VERSION "HIPBNYYYYYYYYYYYYYYYYYYYYYYYYYYYYYYYYYYYYY/4/%%%/4/'%**4YYY///"

NS_ :

BS_:

BU_: WaveSculptor20

BO_ 1024 IDInfo: 8 WaveSculptor20
 SG_ TritiumID : 0|32@1+ (1,0) [0|0] "" Vector__XXX
 SG_ SerialNumber : 32|32@1+ (1,0) [0|0] "" Vector__XXX

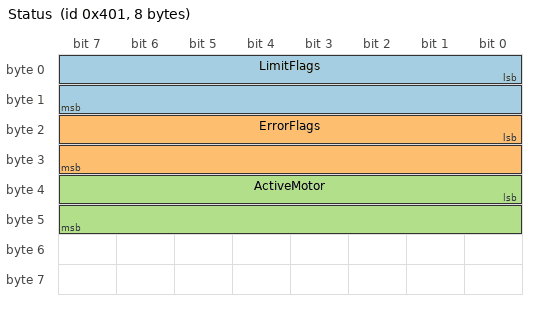
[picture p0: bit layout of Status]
BO_ 1025 Status: 8 WaveSculptor20
 SG_ LimitFlags : 0|16@1+ (1,0) [0|0] "" Vector__XXX
 SG_ ErrorFlags : 16|16@1+ (1,0) [0|0] "" Vector__XXX
 SG_ ActiveMotor : 32|16@1+ (1,0) [0|0] "" Vector__XXX

BO_ 1026 BusMeasurement: 8 WaveSculptor20
 SG_ BusVoltage : 0|32@1- (1,0) [0|0] "V" Vector__XXX
 SG_ BusCurrent : 32|32@1- (1,0) [0|0] "A" Vector__XXX

BO_ 1027 VelocityMeasurement: 8 WaveSculptor20
 SG_ MotorVelocity : 0|32@1- (1,0) [0|0] "rpm" Vector__XXX
 SG_ VehicleVelocity : 32|32@1- (1,0) [0|0] "m/s" Vector__XXX

BO_ 1028 PhaseCurrentMeasurement: 8 WaveSculptor20
 SG_ PhaseCurrentB : 0|32@1- (1,0) [0|0] "A_rms" Vector__XXX
 SG_ PhaseCurrentA : 32|32@1- (1,0) [0|0] "A_rms" Vector__XXX

BO_ 1029 MotorVoltageVectorMeasurement: 8 WaveSculptor20
 SG_ Vq : 0|32@1- (1,0) [0|0] "V" Vector__XXX
 SG_ Vd : 32|32@1- (1,0) [0|0] "V" Vector__XXX

BO_ 1030 MotorCurrentVectorMeasurement: 8 WaveSculptor20
 SG_ Iq : 0|32@1- (1,0) [0|0] "A" Vector__XXX
 SG_ Id : 32|32@1- (1,0) [0|0] "A" Vector__XXX

BO_ 1031 MotorBackEmfMeasurementPrediction: 8 WaveSculptor20
 SG_ BEMFq : 0|32@1- (1,0) [0|0] "V" Vector__XXX
 SG_ BEMFd : 32|32@1- (1,0) [0|0] "V" Vector__XXX

BO_ 1032 VoltageRail15V1V65Measurement: 8 WaveSculptor20
 SG_ Reference1V65 : 0|32@1- (1,0) [0|0] "V" Vector__XXX
 SG_ Supply15V : 32|32@1- (1,0) [0|0] "V" Vector__XXX

BO_ 1033 VoltageRail2V51V2Measurement: 8 WaveSculptor20
 SG_ Supply2V5 : 32|32@1- (1,0) [0|0] "V" Vector__XXX
 SG_ Supply1V2 : 0|32@1- (1,0) [0|0] "V" Vector__XXX

BO_ 1034 FanSpeedMeasurement: 8 WaveSculptor20
 SG_ VoltagePercentage : 0|32@1- (1,0) [0|0] "%" Vector__XXX
 SG_ FanSpeed : 32|32@1- (1,0) [0|0] "rpm" Vector__XXX

BO_ 1035 SinkMotorTempMeasurement: 8 WaveSculptor20
 SG_ MotorTemp : 0|32@1- (1,0) [0|0] "C" Vector__XXX
 SG_ HeatsinkTemp : 32|32@1- (1,0) [0|0] "C" Vector__XXX

BO_ 1036 AirInCpuTempMeasurement: 8 WaveSculptor20
 SG_ ProcessorTemp : 0|32@1- (1,0) [0|0] "C" Vector__XXX
 SG_ AirInletTemp : 32|32@1- (1,0) [0|0] "C" Vector__XXX

BO_ 1037 AirOutCapTempMeasurement: 8 WaveSculptor20
 SG_ CapacitorTemp : 0|32@1- (1,0) [0|0] "C" Vector__XXX
 SG_ AirOutTemp : 32|32@1- (1,0) [0|0] "C" Vector__XXX

BO_ 1038 OdometerBusAhMeasurement: 8 WaveSculptor20
 SG_ Odometer : 0|32@1- (1,0) [0|0] "m" Vector__XXX
 SG_ DCBus : 32|32@1- (1,0) [0|0] "Ah" Vector__XXX

CM_ BU_ WaveSculptor20 "Right motor controller (base address 0x400)";
CM_ SG_ 1024 TritiumID "Device serial number, allocated at manufacture.";
CM_ SG_ 1024 SerialNumber "TRIa stored as a string";
CM_ SG_ 1025 ActiveMotor "The index of the motor currently being used. Driver controls could use this to check against a switch position or to display to the driver if desired.";
CM_ SG_ 1026 BusVoltage "DC bus voltage at the controller.";
CM_ SG_ 1026 BusCurrent "Current drawn from the DC bus by the controller.";
CM_ SG_ 1027 MotorVelocity "Vehicle velocity in metres / second.";
CM_ SG_ 1027 VehicleVelocity "Motor angular frequency in revolutions per minute.";
CM_ SG_ 1028 PhaseCurrentB "RMS current in motor Phase B. ";
CM_ SG_ 1028 PhaseCurrentA "RMS current in motor Phase A.";
CM_ SG_ 1029 Vq "Imaginary component of the applied non-rotating voltage vector to the motor.";
CM_ SG_ 1029 Vd "Real component of the applied non-rotating voltage vector to the motor.";
CM_ SG_ 1030 Iq "Imaginary component of the applied non-rotating current vector to the motor. This current produces torque in the motor and should be in phase with the back-EMF of the motor.";
CM_ SG_ 1030 Id "Real component of the applied non-rotating current vector to the motor. This vector represents the field current of the motor.";
CM_ SG_ 1031 BEMFq "The peak of the phase to neutral motor voltage.";
CM_ SG_ 1031 BEMFd "By definition this value is always 0V.";
CM_ SG_ 1032 Reference1V65 "Actual voltage level of the 1.65V analog reference.";
CM_ SG_ 1032 Supply15V "Actual voltage level of the 15V power rail.";
CM_ SG_ 1033 Supply2V5 "Actual voltage level of the 2.5V FPGA power rail.";
CM_ SG_ 1033 Supply1V2 "Actual voltage level of the 1.2V DSP power rail.";
CM_ SG_ 1034 VoltagePercentage "Drive voltage percentage to cooling fan. If this value is above 0%, then the fan should be spinning.";
CM_ SG_ 1034 FanSpeed "Cooling fan speed in revolutions per minute.";
CM_ SG_ 1035 MotorTemp "Internal temperature of the motor.";
CM_ SG_ 1035 HeatsinkTemp "Surface temperature of the controller heatsink.";
CM_ SG_ 1036 ProcessorTemp "Temperature of the internal processor.";
CM_ SG_ 1036 AirInletTemp "Ambient air temperature at the ventilation inlet of the controller.";
CM_ SG_ 1037 CapacitorTemp "Ambient temperature of the internal bus capacitors. Unused in 20kW WaveSculptor.";
CM_ SG_ 1037 AirOutTemp "Ambient air temperature at the ventilation outlet of the controller. Unused in 20kW WaveSculptor.";
CM_ SG_ 1038 Odometer "The distance the vehicle has travelled since reset";
CM_ SG_ 1038 DCBus "The charge flow into the controller bus voltage from the time of reset.";
BA_DEF_ BO_  "GenMsgCycleTime" INT 2 50000;
BA_DEF_DEF_  "GenMsgCycleTime" 0;
BA_ "GenMsgCycleTime" BO_ 1024 1000;
BA_ "GenMsgCycleTime" BO_ 1025 200;
BA_ "GenMsgCycleTime" BO_ 1026 200;
BA_ "GenMsgCycleTime" BO_ 1027 200;
BA_ "GenMsgCycleTime" BO_ 1028 200;
BA_ "GenMsgCycleTime" BO_ 1029 200;
BA_ "GenMsgCycleTime" BO_ 1030 200;
BA_ "GenMsgCycleTime" BO_ 1031 200;
BA_ "GenMsgCycleTime" BO_ 1032 1000;
BA_ "GenMsgCycleTime" BO_ 1033 1000;
BA_ "GenMsgCycleTime" BO_ 1034 1000;
BA_ "GenMsgCycleTime" BO_ 1035 1000;
BA_ "GenMsgCycleTime" BO_ 1036 5000;
BA_ "GenMsgCycleTime" BO_ 1037 5000;
BA_ "GenMsgCycleTime" BO_ 1038 1000;
SIG_VALTYPE_ 1026 BusVoltage : 1;
SIG_VALTYPE_ 1026 BusCurrent : 1;
SIG_VALTYPE_ 1027 MotorVelocity : 1;
SIG_VALTYPE_ 1027 VehicleVelocity : 1;
SIG_VALTYPE_ 1028 PhaseCurrentB : 1;
SIG_VALTYPE_ 1028 PhaseCurrentA : 1;
SIG_VALTYPE_ 1029 Vq : 1;
SIG_VALTYPE_ 1029 Vd : 1;
SIG_VALTYPE_ 1030 Iq : 1;
SIG_VALTYPE_ 1030 Id : 1;
SIG_VALTYPE_ 1031 BEMFq : 1;
SIG_VALTYPE_ 1031 BEMFd : 1;
SIG_VALTYPE_ 1032 Reference1V65 : 1;
SIG_VALTYPE_ 1032 Supply15V : 1;
SIG_VALTYPE_ 1033 Supply2V5 : 1;
SIG_VALTYPE_ 1033 Supply1V2 : 1;
SIG_VALTYPE_ 1034 VoltagePercentage : 1;
SIG_VALTYPE_ 1034 FanSpeed : 1;
SIG_VALTYPE_ 1035 MotorTemp : 1;
SIG_VALTYPE_ 1035 HeatsinkTemp : 1;
SIG_VALTYPE_ 1036 ProcessorTemp : 1;
SIG_VALTYPE_ 1036 AirInletTemp : 1;
SIG_VALTYPE_ 1037 CapacitorTemp : 1;
SIG_VALTYPE_ 1037 AirOutTemp : 1;
SIG_VALTYPE_ 1038 Odometer : 1;
SIG_VALTYPE_ 1038 DCBus : 1;
